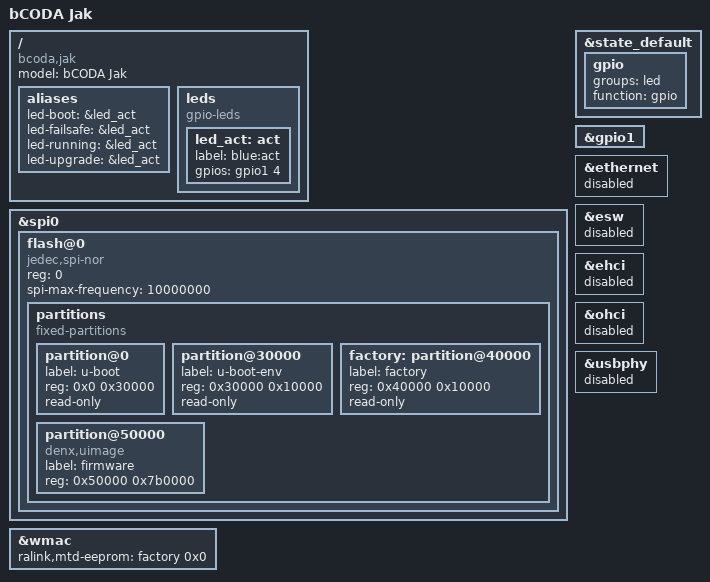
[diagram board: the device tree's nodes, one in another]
#include "rt5350.dtsi"
#include <dt-bindings/gpio/gpio.h>
#include <dt-bindings/input/input.h>

/ {
	compatible = "bcoda,jak", "ralink,rt5350-soc";
	model = "bCODA Jak";
	
	aliases {
            led-boot = &led_act;
            led-failsafe = &led_act;
            led-running = &led_act;
            led-upgrade = &led_act;
    };

    leds {
            compatible = "gpio-leds";

            led_act: act {
                    label = "blue:act";
                    gpios = <&gpio1 4 GPIO_ACTIVE_HIGH>;
            };
    };

    /* blocks boot with usbphy disabled;
       with usbphy enabled resets conflict :-/
    otg: otg@10120000 {
        #address-cells = <1>;
        #size-cells = <0>;
        compatible = "ralink,rt5350-otg", "snps,dwc2";
        reg = <0x10120000 0x1400>;
        interrupt-parent = <&intc>;
        interrupts = <19>;
        status = "okay";        
        dr_mode = "peripheral";
        resets = <&rstctrl 25>;
        reset-names = "dwc2";
    };
    */
    
};

&spi0 {
	status = "okay";

	flash@0 {
		compatible = "jedec,spi-nor";
		reg = <0>;
		spi-max-frequency = <10000000>;

		partitions {
			compatible = "fixed-partitions";
			#address-cells = <1>;
			#size-cells = <1>;

			partition@0 {
				label = "u-boot";
				reg = <0x0 0x30000>;
				read-only;
			};

			partition@30000 {
				label = "u-boot-env";
				reg = <0x30000 0x10000>;
				read-only;
			};

			factory: partition@40000 {
				label = "factory";
				reg = <0x40000 0x10000>;
				read-only;
			};

			partition@50000 {
				compatible = "denx,uimage";
				label = "firmware";
				reg = <0x50000 0x7b0000>;
			};
		};
	};
};

&wmac {
	ralink,mtd-eeprom = <&factory 0x0>;
};

&state_default {
	gpio {
		groups = "led";
		function = "gpio";
	};
};

&gpio1 {
	status = "okay";
};

&ethernet {
	status = "disabled";
};

&esw {
	status = "disabled";
};

&ehci {
	status = "disabled";
};

&ohci {
	status = "disabled";
};

&ohci {
	status = "disabled";
};

&usbphy {
	status = "disabled";
};

